# SAMA7G54D4G device description
Architecture: CORTEX-A7; Family: SAMA; Series: SAMA7G
Registers are 32-bit, read-write, reset 0x0 unless marked. A register's access mark holds for its fields unless they carry their own. Offsets are from the block's base; [hi:lo] are bit positions; {n}, {i} and the like mark numbered series.

## MIPICSI2PHY — Camera Serial Interface 2 Controller and MIPI PHY
Instances: CSI 0xE1400000
0x00 CSI_VERSION ro reset not defined — Read-only register Contains the version of DWC_mipi_csi2_host coded in 32-bit ASCII code.
  [31:0] VERSION — This field indicates the version of the DWC_mipi_csi2_host.
0x04 CSI_N_LANES reset not defined — Static read and write register Configures the number of active lanes that the DWC_mipi_csi2_host uses to receive the camera device data.
  [2:0] N_LANES — Number of active data lanes: -000: 1 Data Lane -001: 2 Data Lanes -010: 3 Data Lanes -011: 4 Data Lanes - Only on D-PHY -100: 5 Data Lanes - Only on D-PHY -101: 6 Data Lanes - Only on D-PHY -110: 7 Data Lanes - Only on D-PHY -111: 8 Data Lanes - Only on D-PHY This can only be updated when the PHY lane is in stopstate.
0x08 CSI_CSI2_RESETN reset not defined — Static read and write register Controls the DWC_mipi_csi2_host logic reset state. When activated, the internal logic of the controller goes into the reset state. The configuration is not reset to default values with this register, instead, only the internal controller logic is affected.
  [0] CSI2_RESETN — DWC_mipi_csi2_host reset output. Active Low.
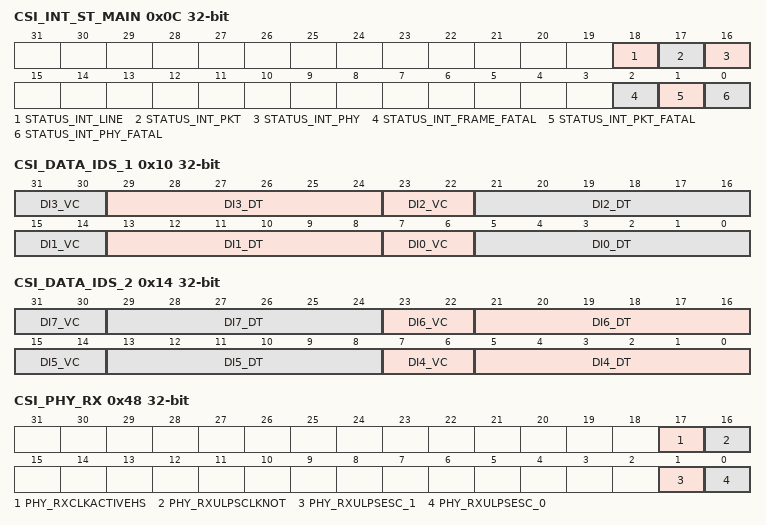
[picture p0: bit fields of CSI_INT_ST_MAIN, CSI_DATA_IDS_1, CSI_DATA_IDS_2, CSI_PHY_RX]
0x0C CSI_INT_ST_MAIN ro reset not defined — Clear on read register Contains the status of individual interrupt sources, regardless of the contents of the associated interrupt mask registers, so it is possible to service the interrupt status registers by polling. Reading INT_ST_MAIN register clears the interrupt pin.
  [18] STATUS_INT_LINE — Status of int_st_line
  [17] STATUS_INT_PKT — Status of int_st_pkt.
  [16] STATUS_INT_PHY — Status of int_st_phy.
  [2] STATUS_INT_FRAME_FATAL — Status of int_st_frame_fatal.
  [1] STATUS_INT_PKT_FATAL — Status of int_st_pkt_fatal.
  [0] STATUS_INT_PHY_FATAL — Status of int_st_phy_fatal.
0x10 CSI_DATA_IDS_1 reset not defined — Static read and write register Programs the data Ids for matching line error reporting. Enables up to eight different data Ids that can be identified simultaneously.
  [8n+7:8n+6] DI{n}_VC (n=0..3) — Virtual channel for programmed data Id {n}.
  [29:24] DI3_DT — Data type for programmed data Id 3.
  [21:16] DI2_DT — Data type for programmed Data ID 2.
  [13:8] DI1_DT — Data type for programmed data Id 1.
  [5:0] DI0_DT — Data type for programmed data Id 0.
0x14 CSI_DATA_IDS_2 reset not defined — Static read and write register Programs the data Ids for matching line error reporting. Configures Data ID definition for four additional pairs of data types and virtual channel identifiers.
  [8n-25:8n-26] DI{n}_VC (n=4..7) — Virtual channel for programmed data Id {n}.
  [8n-27:8n-32] DI{n}_DT (n=4..7) — Data type for programmed data Id {n}.
0x40 CSI_PHY_SHUTDOWNZ reset not defined — Active low Controls the PHY Shutdown mode. In this state, the PHY sets the analog and digital circuitry in the Reset state.
  [0] PHY_SHUTDOWNZ — Shutdown input. This line is used to place the complete macro in power down. All analog blocks are in power down mode and digital logic is cleared. Active Low.
0x44 CSI_DPHY_RSTZ reset not defined — Active low Controls the PHY Reset mode. in this state, the PHY sets the digital circuitry in the Reset State.
  [0] DPHY_RSTZ — PHY reset output. Active Low.
0x48 CSI_PHY_RX ro reset not defined — Read-only register Contains the status of RX-related signals from PHY: RXULPSESC* RXCLKACTIVEHS (D-PHY) It contains information such as, if the clock lane is receiving high-speed clock signal, or if the data and clock lanes are in Ultra Low Power Mode (ULPM).
  [17] PHY_RXCLKACTIVEHS — Indicates that D-PHY clock lane is actively receiving a DDR clock
  [16] PHY_RXULPSCLKNOT — Active Low. This signal indicates that D-PHY Clock Lane module has entered the Ultra Low Power state
  [1] PHY_RXULPSESC_1 — Lane module 1 has entered the Ultra Low Power mode
  [0] PHY_RXULPSESC_0 — Lane module 0 has entered the Ultra Low Power mode.
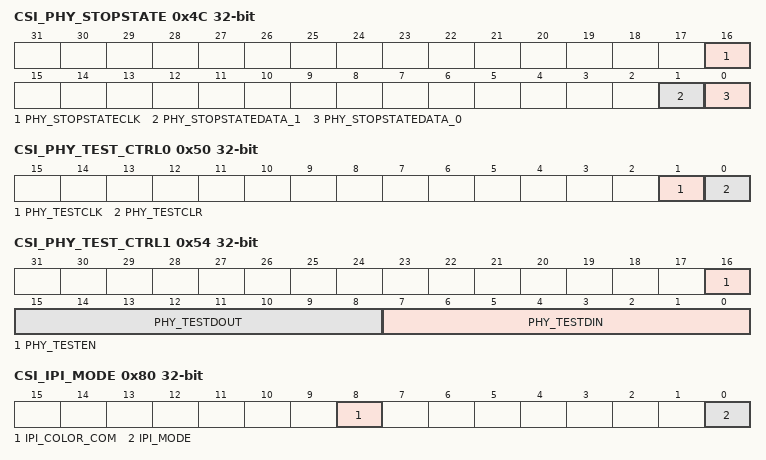
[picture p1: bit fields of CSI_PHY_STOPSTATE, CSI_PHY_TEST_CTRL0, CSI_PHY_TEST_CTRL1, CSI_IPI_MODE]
0x4C CSI_PHY_STOPSTATE ro reset not defined — Read-only register Contains the STOPSTATE signal status from PHY.
  [16] PHY_STOPSTATECLK — D-PHY Clock lane in Stop state
  [1] PHY_STOPSTATEDATA_1 — Data lane 1 in Stop state
  [0] PHY_STOPSTATEDATA_0 — Data lane 0 in Stop state.
0x50 CSI_PHY_TEST_CTRL0 reset not defined — Dynamic register Control for vendor specific interface in the PHY. Controls the Synopsys D-PHY Test and Control interface. This register controls the TESTCLR and TESTCLK signals.
  [1] PHY_TESTCLK — Clock to capture testdin bus contents into the macro, with testen signal controlling the operation selection.
  [0] PHY_TESTCLR — When active, performs vendor specific interface initialization. Active High. Note: This line needs an initial high pulse after power up for analog programmability default values to be preset.
0x54 CSI_PHY_TEST_CTRL1 reset not defined — Dynamic register Control for vendor specific interface in the PHY. Controls the Synopsys D-PHY Test and Control interface. This register controls the TESTENABLE signal and the TESTDIN bus. Reading from this register retrieves the value from TESTDOUT.
  [16] PHY_TESTEN — When asserted high, it configures an address write operation on the falling edge of testclk. When asserted low, it configures a data write operation on the rising edge of testclk.
  [15:8] PHY_TESTDOUT — Vendor-specific 8-bit data output for reading data and other probing functionalities.
  [7:0] PHY_TESTDIN — Test interface 8-bit data input for programming internal registers and accessing test functionalities.
0x80 CSI_IPI_MODE reset not defined — This register selects how the IPI interface generates the video frame
  [8] IPI_COLOR_COM — This field indicates if color mode components are delivered as follows: - 0: 48 bits interface - 1: 16 bits interface
  [0] IPI_MODE — This field indicates the video mode transmission type as follows: - 0: Camera timing - 1: Controller timing
0x84 CSI_IPI_VCID reset not defined — This register selects the virtual channel processed by IPI
  [1:0] IP_VCID — Virtual channel of data to be processed by pixel interface
0x88 CSI_IPI_DATA_TYPE reset not defined — This register selects the data type processed by IPI
  [5:0] IPI_DATA_TYPE — Data type of data to be processed by pixel interface
    0=FS (Frame Start signaling); 1=FE (Frame End signaling); 2=LS (Line Start signaling); 3=LE (Line End signaling); 17=BLANK (Blanking packet); 24=YUV420_8 (YUV420 8-bit data format); 25=YUV420_10 (YUV420 10-bit data format); 26=YUV420_8L (YUV420 8-bit Legacy data format); 28=YUV420_8C (YUV420 8-bit (Chroma Shifted Pixel Sampling) data format); 29=YUV420_10C (YUV420 10-bit (Chroma Shifted Pixel Sampling) data format); 30=YUV422_8 (YUV422 8-bit data format); 31=YUV422_10 (YUV422 10-bit data format); 32=RGB444 (RGB444 data format); 33=RGB555 (RGB555 data format); 34=RGB565 (RGB565 data format); 35=RGB666 (RGB666 data format); 36=RGB888 (RGB888 data format); 40=RAW6 (RAW6 data format); 41=RAW7 (RAW7 data format); 42=RAW8 (RAW8 data format); 43=RAW10 (RAW10 data format); 44=RAW12 (RAW12 data format); 45=RAW14 (RAW14 data format)
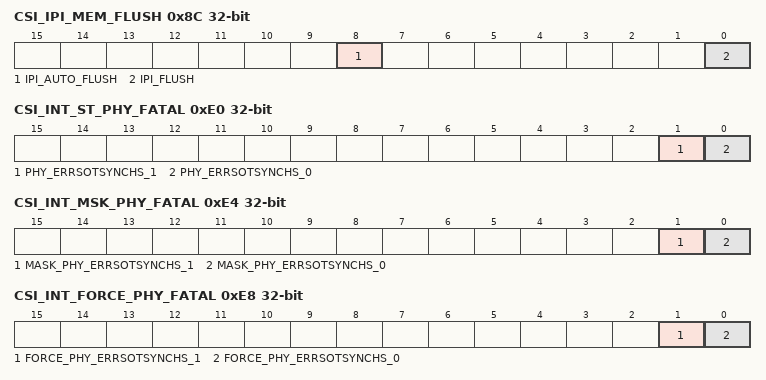
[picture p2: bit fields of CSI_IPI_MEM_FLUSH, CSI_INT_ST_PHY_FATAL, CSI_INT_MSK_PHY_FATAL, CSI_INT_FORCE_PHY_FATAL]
0x8C CSI_IPI_MEM_FLUSH reset not defined — This register control the flush of IPI memory
  [8] IPI_AUTO_FLUSH — Memory is automatically flushed at each vsync
  [0] IPI_FLUSH — Flush IPI memory. This bit is auto clear
0x90 CSI_IPI_HSA_TIME reset not defined — This register configures the video Horizontal Synchronism Active (HSA) time
  [11:0] IPI_HSA_TIME — This field configures the Horizontal Synchronism Active period in pixclk cycles
0x94 CSI_IPI_HBP_TIME reset not defined — This register configures the video Horizontal Back Porch (HBP) time
  [11:0] IPI_HBP_TIME — This field configures the Horizontal Back Porch period in pixclk cycles
0x98 CSI_IPI_HSD_TIME reset not defined — This register configures the video Horizontal Sync Delay (HSD) time
  [11:0] IPI_HSD_TIME — This field configures the Horizontal Sync Porch delay period in pixclk cycles
0x9C CSI_IPI_HLINE_TIME reset not defined — This register configures the overall time for each video line
  [14:0] IPI_HLINE_TIME — This field configures the size of the line time counted in pixclk cycles
0xB0 CSI_IPI_VSA_LINES reset not defined — This register configures the Vertical Synchronism Active (VSA) period
  [9:0] IPI_VSA_LINES — This field configures the Vertical Synchronism Active period measured in number of horizontal lines
0xB4 CSI_IPI_VBP_LINES reset not defined — This register configures the Vertical Back Porch (VBP) period
  [9:0] IPI_VBP_LINES — This field configures the Vertical Back Porch period measured in number of horizontal lines
0xB8 CSI_IPI_VFP_LINES reset not defined — This register configures the Vertical Front Porch (VFP) period
  [9:0] IPI_VFP_LINES — This field configures the Vertical Front Porch period measured in number of horizontal lines
0xBC CSI_IPI_VACTIVE_LINES reset not defined — This register configures the vertical resolution of the video
  [13:0] IPI_VACTIVE_LINES — This field configures the Vertical Active period measured in number of horizontal lines
0xCC CSI_PHY_CAL ro reset not defined — Clear on read register Contains the CALIBRATION signal status from Synopsys D-PHY.
  [0] RXSKEWCALHS — A low-to-high transition on rxskewcalhs signal means that the PHY has initiated the de-skew calibration..
0xE0 CSI_INT_ST_PHY_FATAL ro reset not defined — Clear on read register Groups the fatal interruptions caused by PHY Packet discarded. Stores the source of the error. Reading INT_ST_PHY_FATAL register does not clear the interrupt pin.
  [1] PHY_ERRSOTSYNCHS_1 — Start of transmission error on data lane 1 (no synchronization achieved)
  [0] PHY_ERRSOTSYNCHS_0 — Start of transmission error on data lane 0 (no synchronization achieved).
0xE4 CSI_INT_MSK_PHY_FATAL reset not defined — Static read and write register Interrupt mask for INT_ST_PHY_FATAL controls which interrupt status bits will trigger the interrupt pin. Bit at 1 - Enable the interrupt source. Bit at 0 - Interrupt source is masked.
  [1] MASK_PHY_ERRSOTSYNCHS_1 — Mask for phy_errsotsynchs_1
  [0] MASK_PHY_ERRSOTSYNCHS_0 — Mask for phy_errsotsynchs_0.
0xE8 CSI_INT_FORCE_PHY_FATAL reset not defined — Static read and write register Interrupt Force register is used for test purposes, and allows triggering INT_ST_PHY_FATAL interrupt events individually, without the need to activate the conditions that trigger the interrupt sources, since it may be extremely complex to generate stimuli for that purpose.
  [1] FORCE_PHY_ERRSOTSYNCHS_1, [0] FORCE_PHY_ERRSOTSYNCHS_0
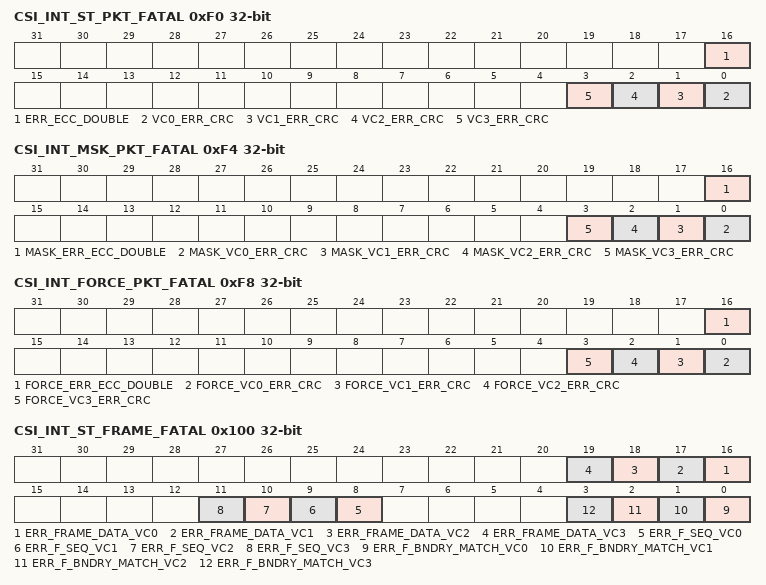
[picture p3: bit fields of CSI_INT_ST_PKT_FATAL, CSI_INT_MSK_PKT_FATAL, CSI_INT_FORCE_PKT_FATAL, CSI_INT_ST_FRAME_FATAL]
0xF0 CSI_INT_ST_PKT_FATAL ro reset not defined — Clear on read register Groups the fatal interruption related with Packet construction. Packet discarded. Notifies which interruption bit has caused the interruption. Stores the source of the error. Reading INT_ST_PKT_FATAL register does not clear the interrupt pin.
  [16] ERR_ECC_DOUBLE — D-PHY mode : Header ECC contains at least 2 errors, unrecoverable. C-PHY mode : Header CRC unrecoverable.
  [n] VC{n}_ERR_CRC (n=0..3) — Payload Checksum error detected on virtual channel {n}.
0xF4 CSI_INT_MSK_PKT_FATAL reset not defined — Static read and write register Interrupt mask for INT_ST_PKT_FATAL controls which interrupt status bits will trigger the interrupt pin. Bit at 1 - Enable the interrupt source. Bit at 0 - Interrupt source is masked.
  [16] MASK_ERR_ECC_DOUBLE — Mask for err_ecc_double.
  [n] MASK_VC{n}_ERR_CRC (n=0..3) — Mask for vc{n}_err_crc.
0xF8 CSI_INT_FORCE_PKT_FATAL reset not defined — Static read and write register Interrupt force register is used for test purposes, and allows triggering INT_ST_PKT_FATAL interrupt events individually, without the need to activate the conditions that trigger the interrupt sources, since it may be extremely complex to generate stimuli for that purpose.
  [16] FORCE_ERR_ECC_DOUBLE, [n] FORCE_VC{n}_ERR_CRC (n=0..3)
0x100 CSI_INT_ST_FRAME_FATAL ro reset not defined — Clear on read register Fatal interruption related with Frame construction. Packet discarded. Groups and notifies which interruption bits caused the interruption. Stores the source of the error. Reading INT_ST_FRAME_FATAL register does not clear the interrupt pin.
  [n+16] ERR_FRAME_DATA_VC{n} (n=0..3) — Last received Frame in virtual channel {n}, had at least one CRC error.
  [n+8] ERR_F_SEQ_VC{n} (n=0..3) — Incorrect Frame sequence detected in Virtual Channel {n}.
  [n] ERR_F_BNDRY_MATCH_VC{n} (n=0..3) — Error matching Frame Start with Frame End for virtual channel {n}.
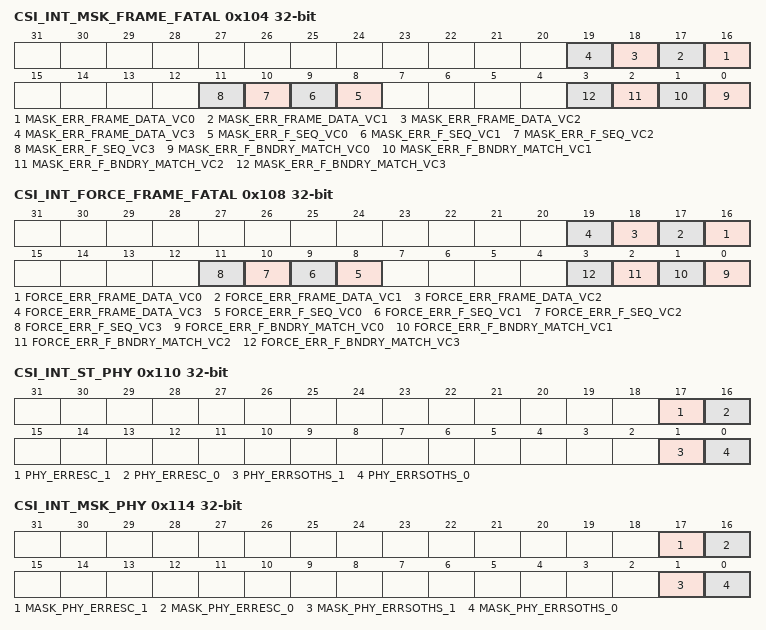
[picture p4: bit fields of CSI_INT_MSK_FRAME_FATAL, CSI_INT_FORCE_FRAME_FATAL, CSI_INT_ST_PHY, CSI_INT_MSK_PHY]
0x104 CSI_INT_MSK_FRAME_FATAL reset not defined — Static read and write register Interrupt mask for INT_ST_FRAME_FATAL controls which interrupt status bits will trigger the interrupt pin. Bit at 1 - Enable the interrupt source. Bit at 0 - Interrupt source is masked.
  [n+16] MASK_ERR_FRAME_DATA_VC{n} (n=0..3) — Mask for err_frame_data_vc{n}.
  [n+8] MASK_ERR_F_SEQ_VC{n} (n=0..3) — Mask for err_f_seq_vc{n}.
  [n] MASK_ERR_F_BNDRY_MATCH_VC{n} (n=0..3) — Mask for err_f_bndry_match_vc{n}.
0x108 CSI_INT_FORCE_FRAME_FATAL reset not defined — Static read and write register Interrupt force register is used for test purposes, and allows triggering INT_ST_FRAME_FATAL interrupt events individually, without the need to activate the conditions that trigger the interrupt sources, because it may be extremely complex to generate stimuli for that purpose.
  [n+16] FORCE_ERR_FRAME_DATA_VC{n} (n=0..3), [n+8] FORCE_ERR_F_SEQ_VC{n} (n=0..3), [n] FORCE_ERR_F_BNDRY_MATCH_VC{n} (n=0..3)
0x110 CSI_INT_ST_PHY ro reset not defined — Clear on read register Interruption caused by PHY. Groups and notifies which interruption bits caused the interruption. Stores the source of the error. Reading INT_ST_PHY register does not clear the interrupt pin.
  [17] PHY_ERRESC_1 — Start of Transmission Error on data lane 1 (no synchronization achieved)
  [16] PHY_ERRESC_0 — Start of Transmission Error on data lane 0 (no synchronization achieved).
  [1] PHY_ERRSOTHS_1 — Start of transmission error on data lane 1 (synchronization can still be achieved)
  [0] PHY_ERRSOTHS_0 — Start of transmission error on data lane 0 (synchronization can still be achieved).
0x114 CSI_INT_MSK_PHY reset not defined — Static read and write register Interrupt mask for INT_ST_PHY controls which interrupt status bits will trigger the interrupt pin. Bit at 1 - Enable the interrupt source. Bit at 0 - Interrupt source is masked.
  [17] MASK_PHY_ERRESC_1 — Mask for phy_erresc_1
  [16] MASK_PHY_ERRESC_0 — Mask for phy_erresc_0.
  [1] MASK_PHY_ERRSOTHS_1 — Mask for phy_errsoths_1
  [0] MASK_PHY_ERRSOTHS_0 — Mask for phy_errsoths_0.
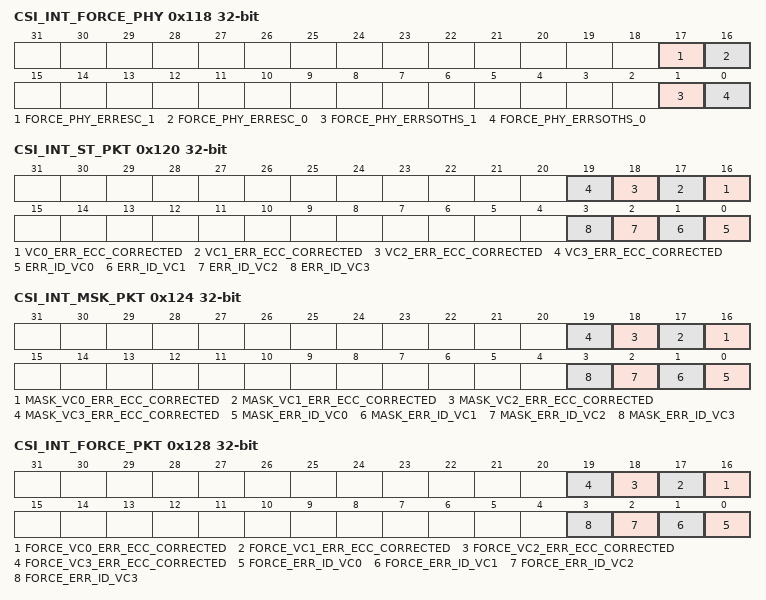
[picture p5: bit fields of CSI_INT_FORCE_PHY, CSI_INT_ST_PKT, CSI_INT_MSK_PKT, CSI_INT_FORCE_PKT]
0x118 CSI_INT_FORCE_PHY reset not defined — Static read and write register Interrupt force register is used for test purposes, and allows triggering INT_ST_PHY interrupt events individually, without the need to activate the conditions that trigger the interrupt sources, because it may be extremely complex to generate stimuli for that purpose.
  [17] FORCE_PHY_ERRESC_1, [16] FORCE_PHY_ERRESC_0, [1] FORCE_PHY_ERRSOTHS_1, [0] FORCE_PHY_ERRSOTHS_0
0x120 CSI_INT_ST_PKT ro reset not defined — Clear on read register Interruption related with Packet construction. Packet discarded. Groups and notifies which interruption bits caused the interruption. Stores the source of the error. Reading INT_ST_PKT register does not clear the interrupt pin.
  [n+16] VC{n}_ERR_ECC_CORRECTED (n=0..3) — D-PHY mode : Header error detected and corrected on virtual channel {n}. C-PHY mode : Header CRC recoverable on virtual channel {n}.
  [n] ERR_ID_VC{n} (n=0..3) — Unrecognized or unimplemented data type detected in virtual channel {n}.
0x124 CSI_INT_MSK_PKT reset not defined — Static read and write register Interrupt mask for INT_ST_PKT controls which interrupt status bits will trigger the interrupt pin. Bit at 1 - Enable the interrupt source. Bit at 0 - Interrupt source is masked.
  [n+16] MASK_VC{n}_ERR_ECC_CORRECTED (n=0..3) — Mask for vc{n}_err_ecc_corrected.
  [n] MASK_ERR_ID_VC{n} (n=0..3) — Mask for err_id_vc{n}.
0x128 CSI_INT_FORCE_PKT reset not defined — Static read and write register Interrupt force register is used for test purposes, and allows triggering INT_ST_PKT interrupt events individually, without the need to activate the conditions that trigger the interrupt sources, because it may be extremely complex to generate stimuli for that purpose.
  [n+16] FORCE_VC{n}_ERR_ECC_CORRECTED (n=0..3), [n] FORCE_ERR_ID_VC{n} (n=0..3)
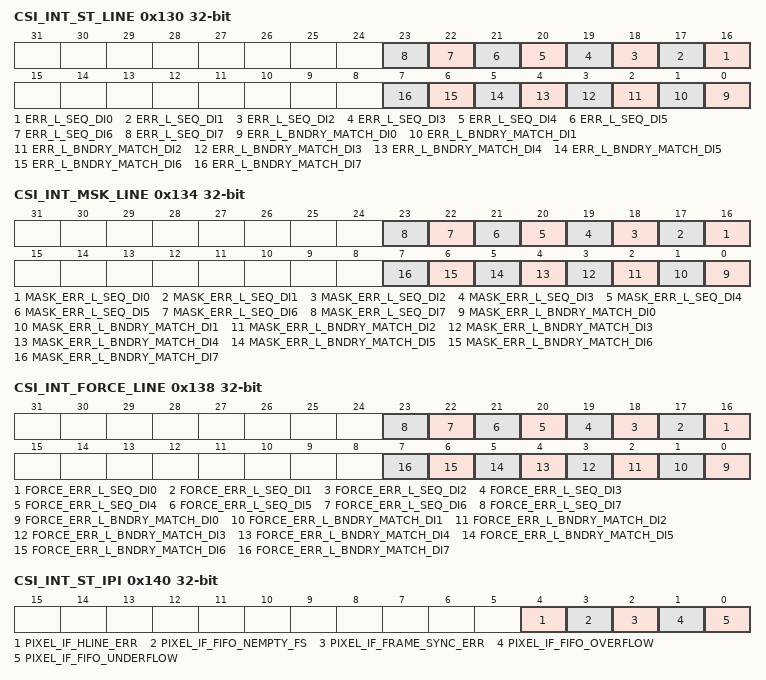
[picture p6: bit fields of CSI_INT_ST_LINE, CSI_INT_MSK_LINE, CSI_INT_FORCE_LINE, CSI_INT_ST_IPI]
0x130 CSI_INT_ST_LINE ro reset not defined — Clear on read register Interruption related with Line construction. Groups and notifies which interruption bits caused the interruption. Stores the source of the error. Reading INT_ST_LINE register does not clear the interrupt pin.
  [n+16] ERR_L_SEQ_DI{n} (n=0..7) — Error in the sequence of lines for vc{n} and dt{n}
  [n] ERR_L_BNDRY_MATCH_DI{n} (n=0..7) — Error matching line start with line end for vc{n} and dt{n}
0x134 CSI_INT_MSK_LINE reset not defined — Static read and write register Interrupt mask for INT_ST_LINE controls which interrupt status bits will trigger the interrupt pin. Bit at 1 - Enable the interrupt source. Bit at 0 - Interrupt source is masked.
  [n+16] MASK_ERR_L_SEQ_DI{n} (n=0..7) — Mask for err_l_seq_di{n}
  [n] MASK_ERR_L_BNDRY_MATCH_DI{n} (n=0..7) — Mask for err_l_bndry_match_di{n}
0x138 CSI_INT_FORCE_LINE reset not defined — Static read and write register Interrupt force register is used for test purposes, and allows triggering INT_ST_LINE interrupt events individually, without the need to activate the conditions that trigger the interrupt sources, because it may be extremely complex to generate stimuli for that purpose.
  [n+16] FORCE_ERR_L_SEQ_DI{n} (n=0..7), [n] FORCE_ERR_L_BNDRY_MATCH_DI{n} (n=0..7)
0x140 CSI_INT_ST_IPI ro reset not defined — Clear on read register Fatal Interruption caused by IPI interface. Groups and notifies which interruption bits caused the interruption. Stores the source of the error. Reading INT_ST_IPI register does not clear the interrupt pin
  [4] PIXEL_IF_HLINE_ERR — Horizontal line time error (only available in controller mode)
  [3] PIXEL_IF_FIFO_NEMPTY_FS — The FIFO of pixel interface is not empty at the start of a new frame. If this is expected this interrupt should be masked
  [2] PIXEL_IF_FRAME_SYNC_ERR — New frame is received but previous has not been completed
  [1] PIXEL_IF_FIFO_OVERFLOW — The FIFO of pixel interface has lost information because some more data arrived when it was full
  [0] PIXEL_IF_FIFO_UNDERFLOW — The FIFO has become empty before the expected number of pixels (calculated from the packet's header) could be extracted to the pixel interface
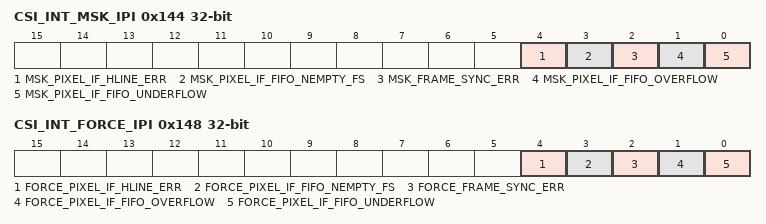
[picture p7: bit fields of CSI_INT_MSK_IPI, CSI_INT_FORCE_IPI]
0x144 CSI_INT_MSK_IPI reset not defined — Static read and write register Each bit of this register masks the interruption from INT_ST_IPI from generating an interruption event. Once a bit of the mask is active, the respective error of the INT_ST_ IPI register is masked preventing the error signal from signaling an interruption through the interrupt pin
  [4] MSK_PIXEL_IF_HLINE_ERR — Mask pixel_if_hline_err
  [3] MSK_PIXEL_IF_FIFO_NEMPTY_FS — Mask pixel_if_fifo_nempty_fs
  [2] MSK_FRAME_SYNC_ERR — Mask for pixel_if_frame_sync_err
  [1] MSK_PIXEL_IF_FIFO_OVERFLOW — Mask for pixel_if_fifo_overflow
  [0] MSK_PIXEL_IF_FIFO_UNDERFLOW — Mask for pixel_if_fifo_underflow
0x148 CSI_INT_FORCE_IPI reset not defined — Static read and write register Interrupt force register is used for test purposes, and allows triggering INT_ST_IPI interrupt events individually, without the need to activate the conditions that trigger the interrupt sources, because it may be extremely complex to generate stimuli for that purpose
  [4] FORCE_PIXEL_IF_HLINE_ERR
  [3] FORCE_PIXEL_IF_FIFO_NEMPTY_FS
  [2] FORCE_FRAME_SYNC_ERR — Force for frame_sync_err
  [1] FORCE_PIXEL_IF_FIFO_OVERFLOW — Force for pixel_if_fifo_overflow
  [0] FORCE_PIXEL_IF_FIFO_UNDERFLOW — Force for pixel_if_fifo_underflow
0x300 CSI_SCRAMBLING reset not defined — This register configures the De-scrambler block.
  [0] SCRAMBLE_ENABLE — Enables data de-scrambling on the controller side.
0x304 CSI_SCRAMBLING_SEED1 reset not defined — This register configures the seed used by De-scrambler block for lane 1
  [15:0] SCRAMBLE_SEED_LANE1 — Seed used by De-scrambler block for lane 1
0x308 CSI_SCRAMBLING_SEED2 reset not defined — This register configures the seed used by De-scrambler block for lane 2
  [15:0] SCRAMBLE_SEED_LANE2 — Seed used by De-scrambler block for lane 2
